# CH32X315 register map
Vendor: WCH Ltd.; File version: 1.1
Registers are 32-bit, read-write, reset 0x0 unless marked. A register's access mark holds for its fields unless they carry their own. Offsets are from the block's base; [hi:lo] are bit positions.

## ARGB
Base 0x40023400
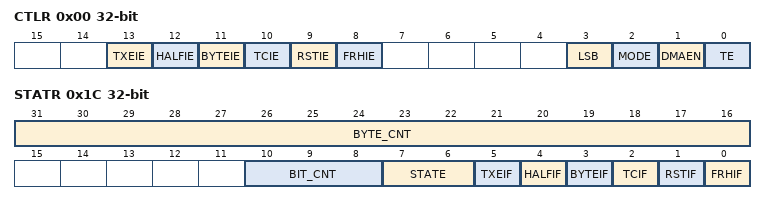
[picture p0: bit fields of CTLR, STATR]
0x00 CTLR — ARGB Control Register
  [13] TXEIE — Send buffer empty interrupt enable
  [12] HALFIE — Data Brush Sends More Than Half Interrupt Enable
  [11] BYTEIE — Byte send completion interrupt enable
  [10] TCIE — Send completion interrupt enable
  [9] RSTIE — RESET code sending is interrupted
  [8] FRHIE — Data refresh cycle end interrupt enabled
  [3] LSB — Data Send Mode Enabling Bits
  [2] MODE — Send mode configuration bits
  [1] DMAEN — DMA Enables
  [0] TE — Send Enable
0x04 DAT_ARR reset 0xFFF — ARGB 0/1 Code Period Configuration Register
  [11:0] DAT_ARR — 0/1 yard cycle
0x08 RST_ARR reset 0x1FFFF — ARGB RESET Code Width Configuration Register
  [16:0] RST_ARR — 0/1 yard cycle
0x0C CCRL — High Level T0H Width Configuration Register
  [11:0] CCRL — 0 yard high level T0H width
0x10 CCRH — 1-yard high-level T1H width configuration register for ARGB
  [11:0] CCRH — 1 yard high level T1H width
0x14 DAT_CYC — ARGB Data Refresh Cycle Length Configuration Register
  [15:0] DAT_CYC — ARGB data refresh cycle length in bytes
0x18 DATAR — ARGB Data Register
  [7:0] DATA — ARGB sends data
0x1C STATR access per field — ARGB State Register
  [31:16] BYTE_CNT ro — Send byte counters
  [10:8] BIT_CNT rw — Send bit counter
  [7:6] STATE ro — State machine indication signal
  [5] TXEIF ro — Send a buffer empty interrupt flag, writing DATAR will clear the subflag
  [4] HALFIF rw — Send more than half of the interrupt flag, write 1 to clear
  [3] BYTEIF rw — The byte sending completion interrupt mark, write 1 to clear
  [2] TCIF rw — Send the interrupt sign completed, write 1 to clear
  [1] RSTIF rw — RESET code sends the interrupt mark, writes 1 to clear
  [0] FRHIF rw — The data refresh cycle has been sent to the interrupt signal, and 1 is written to clear it
0x20 CNTR ro — ARGB Counter Register
  [16:0] CNT — ARGB base counter

## CRC — CRC calculation unit
Base 0x40023000
0x00 DATAR reset 0xFFFFFFFF — Data register
  [31:0] DR — Data Register
0x04 IDATAR 8-bit — Independent Data register
  [7:0] IDR
0x08 CTLR wo — Control register
  [0] RST — Reset bit

## RTC — Real time clock
Base 0x40002800
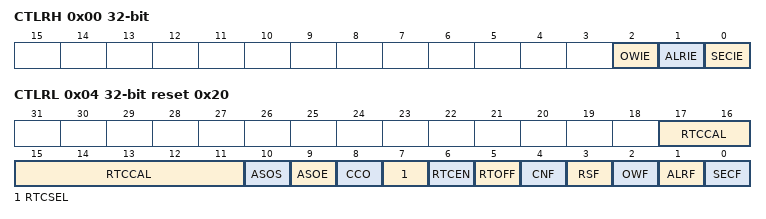
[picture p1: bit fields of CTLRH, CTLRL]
0x00 CTLRH — RTC Control Register High
  [2] OWIE — Overflow interrupt Enable
  [1] ALRIE — Alarm interrupt Enable
  [0] SECIE — Second interrupt Enable
0x04 CTLRL access per field reset 0x20 — RTC Control Register Low
  [17:11] RTCCAL rw — RTC calibration value
  [10] ASOS rw — Alarm or second output selection
  [9] ASOE rw — Alarm or second output enable
  [8] CCO rw — Calibration Clock Output
  [7] RTCSEL rw — RTC clock source selection
  [6] RTCEN rw — RTC clock enable
  [5] RTOFF ro — RTC operation OFF
  [4] CNF rw — Configuration Flag
  [3] RSF rw — Registers Synchronized Flag
  [2] OWF rw — Overflow Flag
  [1] ALRF rw — Alarm Flag
  [0] SECF rw — Second Flag
0x08 PSCRH wo — RTC Prescaler Load Register High
  [3:0] PRL
0x0C PSCRL wo reset 0x8000 — RTC Prescaler Load Register Low
  [15:0] PRL — RTC Prescaler Divider Register Low
0x10 DIVH ro — RTC Prescaler Divider Register High
  [3:0] DIV — RTC prescaler divider register high
0x14 DIVL ro — RTC Prescaler Divider Register Low
  [15:0] DIV — RTC prescaler divider register Low
0x18 CNTH — RTC Counter Register High
  [15:0] CNT — RTC counter register high
0x1C CNTL — RTC Counter Register Low
  [15:0] CNT — RTC counter register Low
0x20 ALRMH wo — RTC Alarm Register High
  [15:0] ALR — RTC alarm register high
0x24 ALRML wo — RTC Alarm Register Low
  [15:0] ALR — RTC alarm register low

## IWDG — Independent watchdog
Base 0x40003000
0x00 CTLR wo — Key register (IWDG_CTLR)
  [15:0] KEY — Key value
0x04 PSCR — Prescaler register (IWDG_PSCR)
  [2:0] PR — Prescaler divider
0x08 RLDR reset 0xFFF — Reload register (IWDG_RLDR)
  [11:0] RL — Watchdog counter reload value
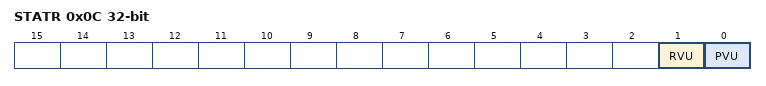
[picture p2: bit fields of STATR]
0x0C STATR ro — Status register (IWDG_SR)
  [1] RVU — Watchdog counter reload value update
  [0] PVU — Watchdog prescaler value update
